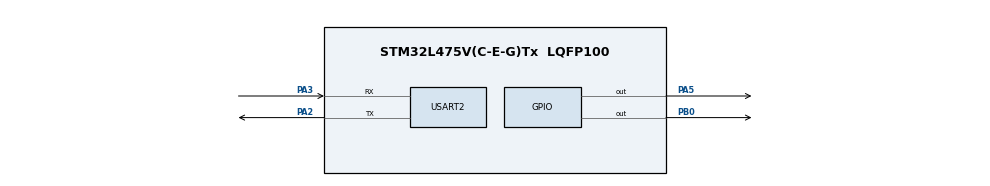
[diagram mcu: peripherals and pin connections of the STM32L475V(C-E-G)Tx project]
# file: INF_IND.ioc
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Mcu.Family=STM32L4
Mcu.Name=STM32L475V(C-E-G)Tx
Mcu.Package=LQFP100
NVIC.PriorityGroup=NVIC_PRIORITYGROUP_4
PA2.Mode=Asynchronous
PA2.Signal=USART2_TX
PA3.Mode=Asynchronous
PA3.Signal=USART2_RX
PA5.Signal=GPIO_Output
PB0.Signal=GPIO_Output
ProjectManager.HeapSize=0x200
ProjectManager.StackSize=0x400
ProjectManager.TargetToolchain=STM32CubeIDE
RCC.HSE_VALUE=8000000
RCC.HSI_VALUE=16000000
RCC.LSE_VALUE=32768
RCC.MSI_VALUE=4000000
RCC.VCOOutputFreq_Value=32000000
USART2.VirtualMode-Asynchronous=VM_ASYNC
board=custom

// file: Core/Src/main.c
#include "main.h"
#include <string.h>  // per strlen()

UART_HandleTypeDef huart2;

void SystemClock_Config(void);
static void MX_GPIO_Init(void);
static void MX_USART2_UART_Init(void);

/* USER CODE BEGIN 0 */
char msg[] = "USER button pressed!\r\n";
/* USER CODE END 0 */

int main(void)
{
    HAL_Init();
    SystemClock_Config();
    MX_GPIO_Init();
    MX_USART2_UART_Init();

    while (1)
    {
        /* Lampeggio LED onboard PA5 */
        HAL_GPIO_TogglePin(GPIOA, GPIO_PIN_5);
        HAL_Delay(500);

        /* Controllo pulsante USER (PA0) */
        if (HAL_GPIO_ReadPin(GPIOA, GPIO_PIN_0) == GPIO_PIN_SET)
        {
            /* Lampeggio LED PB0 */
            HAL_GPIO_TogglePin(GPIOB, GPIO_PIN_0);

            /* Invia messaggio UART */
            HAL_UART_Transmit(&huart2, (uint8_t*)msg, strlen(msg), HAL_MAX_DELAY);

            /* Delay anti-rimbalzo */
            HAL_Delay(200);
        }
    }
}

/* GPIO initialization function */
static void MX_GPIO_Init(void)
{
    GPIO_InitTypeDef GPIO_InitStruct = {0};

    /* GPIO Ports Clock Enable */
    __HAL_RCC_GPIOA_CLK_ENABLE();
    __HAL_RCC_GPIOB_CLK_ENABLE();

    /* Configura LED onboard PA5 */
    GPIO_InitStruct.Pin = GPIO_PIN_5;
    GPIO_InitStruct.Mode = GPIO_MODE_OUTPUT_PP;
    GPIO_InitStruct.Pull = GPIO_NOPULL;
    GPIO_InitStruct.Speed = GPIO_SPEED_FREQ_LOW;
    HAL_GPIO_Init(GPIOA, &GPIO_InitStruct);

    /* Configura LED esterno PB0 */
    GPIO_InitStruct.Pin = GPIO_PIN_0;
    GPIO_InitStruct.Mode = GPIO_MODE_OUTPUT_PP;
    GPIO_InitStruct.Pull = GPIO_NOPULL;
    GPIO_InitStruct.Speed = GPIO_SPEED_FREQ_LOW;
    HAL_GPIO_Init(GPIOB, &GPIO_InitStruct);

    /* Configura USER BUTTON PA0 */
    GPIO_InitStruct.Pin = GPIO_PIN_0;
    GPIO_InitStruct.Mode = GPIO_MODE_INPUT;
    GPIO_InitStruct.Pull = GPIO_NOPULL; // se serve usare GPIO_PULLUP
    HAL_GPIO_Init(GPIOA, &GPIO_InitStruct);
}

/* USART2 initialization function */
static void MX_USART2_UART_Init(void)
{
    huart2.Instance = USART2;
    huart2.Init.BaudRate = 115200;
    huart2.Init.WordLength = UART_WORDLENGTH_8B;
    huart2.Init.StopBits = UART_STOPBITS_1;
    huart2.Init.Parity = UART_PARITY_NONE;
    huart2.Init.Mode = UART_MODE_TX_RX;
    huart2.Init.HwFlowCtl = UART_HWCONTROL_NONE;
    huart2.Init.OverSampling = UART_OVERSAMPLING_16;
    huart2.AdvancedInit.AdvFeatureInit = UART_ADVFEATURE_NO_INIT;
    if (HAL_UART_Init(&huart2) != HAL_OK)
    {
        Error_Handler();
    }
}

/* System Clock Configuration */
void SystemClock_Config(void)
{
    RCC_OscInitTypeDef RCC_OscInitStruct = {0};
    RCC_ClkInitTypeDef RCC_ClkInitStruct = {0};

    /* Configura oscillatore MSI */
    RCC_OscInitStruct.OscillatorType = RCC_OSCILLATORTYPE_MSI;
    RCC_OscInitStruct.MSIState = RCC_MSI_ON;
    RCC_OscInitStruct.MSICalibrationValue = 0;
    RCC_OscInitStruct.MSIClockRange = RCC_MSIRANGE_6;
    RCC_OscInitStruct.PLL.PLLState = RCC_PLL_NONE;
    if (HAL_RCC_OscConfig(&RCC_OscInitStruct) != HAL_OK)
    {
        Error_Handler();
    }

    /* Configura bus clock */
    RCC_ClkInitStruct.ClockType = RCC_CLOCKTYPE_HCLK|RCC_CLOCKTYPE_SYSCLK
                                |RCC_CLOCKTYPE_PCLK1|RCC_CLOCKTYPE_PCLK2;
    RCC_ClkInitStruct.SYSCLKSource = RCC_SYSCLKSOURCE_MSI;
    RCC_ClkInitStruct.AHBCLKDivider = RCC_SYSCLK_DIV1;
    RCC_ClkInitStruct.APB1CLKDivider = RCC_HCLK_DIV1;
    RCC_ClkInitStruct.APB2CLKDivider = RCC_HCLK_DIV1;
    if (HAL_RCC_ClockConfig(&RCC_ClkInitStruct, FLASH_LATENCY_0) != HAL_OK)
    {
        Error_Handler();
    }
}

/* Error Handler */
void Error_Handler(void)
{
    __disable_irq();
    while (1)
    {
    }
}
